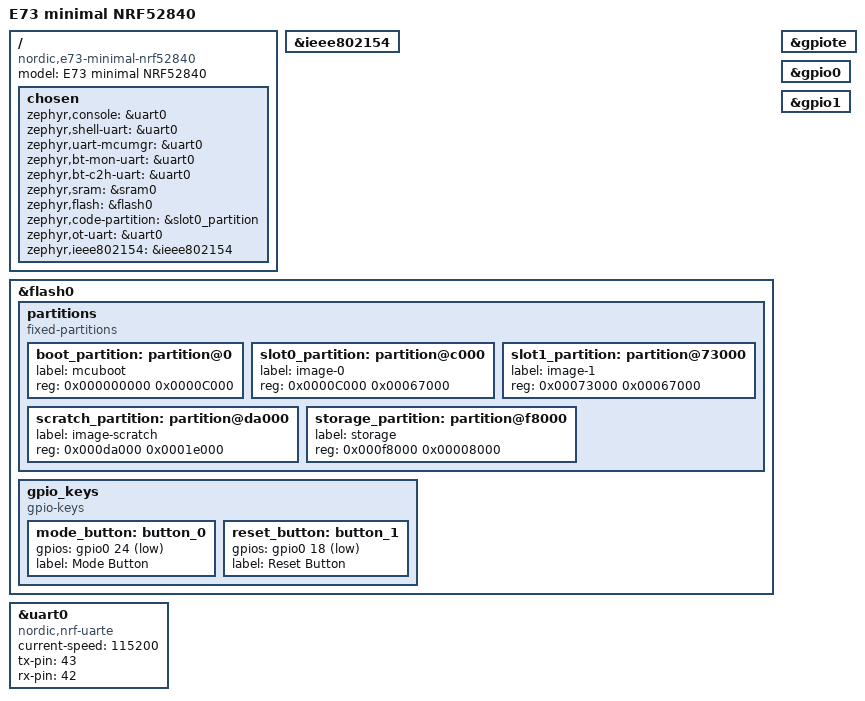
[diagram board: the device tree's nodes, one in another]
/*
 * Copyright (c) 2018 Nordic Semiconductor ASA
 * Copyright (c) 2017 Linaro Limited
 *
 * SPDX-License-Identifier: Apache-2.0
 */

/dts-v1/;
#include <nordic/nrf52840_qiaa.dtsi>

/ {
	model = "E73 minimal NRF52840";
	compatible = "nordic,e73-minimal-nrf52840";

	chosen {
		zephyr,console = &uart0;
		zephyr,shell-uart = &uart0;
		zephyr,uart-mcumgr = &uart0;
		zephyr,bt-mon-uart = &uart0;
		zephyr,bt-c2h-uart = &uart0;
		zephyr,sram = &sram0;
		zephyr,flash = &flash0;
		zephyr,code-partition = &slot0_partition;
		zephyr,ot-uart = &uart0;
		zephyr,ieee802154 = &ieee802154;
	};
};

&ieee802154 {
	status = "okay";
};

&flash0 {
	partitions {
		compatible = "fixed-partitions";
		#address-cells = <1>;
		#size-cells = <1>;

		boot_partition: partition@0 {
			label = "mcuboot";
			reg = <0x000000000 0x0000C000>;
		};
		slot0_partition: partition@c000 {
			label = "image-0";
			reg = <0x0000C000 0x00067000>;
		};
		slot1_partition: partition@73000 {
			label = "image-1";
			reg = <0x00073000 0x00067000>;
		};
		scratch_partition: partition@da000 {
			label = "image-scratch";
			reg = <0x000da000 0x0001e000>;
		};

		/*
		 * The flash starting at 0x000f8000 and ending at
		 * 0x000fffff is reserved for use by the application.
		 */

		/*
		 * Storage partition will be used by FCB/LittleFS/NVS
		 * if enabled.
		 */
		storage_partition: partition@f8000 {
			label = "storage";
			reg = <0x000f8000 0x00008000>;
		};
	};
	gpio_keys {
		compatible = "gpio-keys";
		mode_button: button_0 {
			gpios = <&gpio0 24 (GPIO_PULL_UP | GPIO_ACTIVE_LOW)>;
			label = "Mode Button";
		};

		reset_button: button_1 {
				gpios = <&gpio0 18 (GPIO_PULL_UP | GPIO_ACTIVE_LOW)>;
				label = "Reset Button";
		};
	 
	};
};

&gpiote {
	status = "okay";
};

&gpio0 {
	status = "okay";
};

&gpio1 {
	status = "okay";
};

&uart0 {
	compatible = "nordic,nrf-uarte";
	status = "okay";
	current-speed = <115200>;
	tx-pin = <43>;
	rx-pin = <42>;
};





